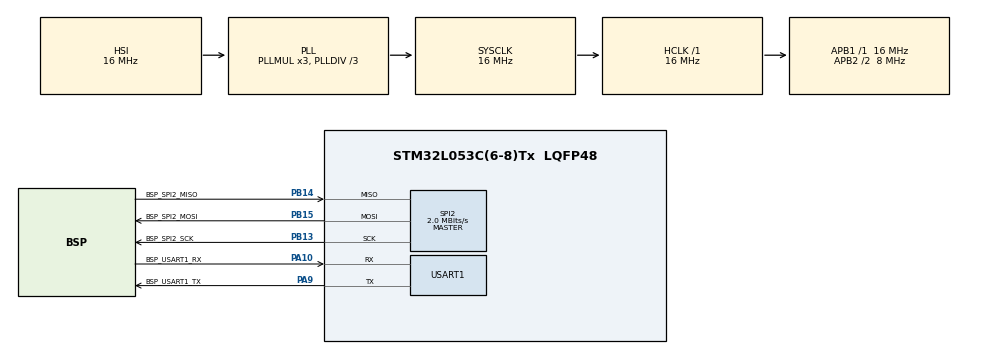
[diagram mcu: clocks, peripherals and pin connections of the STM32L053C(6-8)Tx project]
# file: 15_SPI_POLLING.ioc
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Mcu.Family=STM32L0
Mcu.Name=STM32L053C(6-8)Tx
Mcu.Package=LQFP48
PA10.GPIO_Label=BSP_USART1_RX
PA10.Mode=Asynchronous
PA10.Signal=USART1_RX
PA9.GPIO_Label=BSP_USART1_TX
PA9.Mode=Asynchronous
PA9.Signal=USART1_TX
PB13.GPIO_Label=BSP_SPI2_SCK
PB13.Mode=Full_Duplex_Master
PB13.Signal=SPI2_SCK
PB14.GPIO_Label=BSP_SPI2_MISO
PB14.Mode=Full_Duplex_Master
PB14.Signal=SPI2_MISO
PB15.GPIO_Label=BSP_SPI2_MOSI
PB15.Mode=Full_Duplex_Master
PB15.Signal=SPI2_MOSI
ProjectManager.HeapSize=0x200
ProjectManager.StackSize=0x400
ProjectManager.TargetToolchain=STM32CubeIDE
RCC.AHBFreq_Value=16000000
RCC.APB1Freq_Value=16000000
RCC.APB1TimFreq_Value=16000000
RCC.APB2CLKDivider=RCC_HCLK_DIV2
RCC.APB2Freq_Value=8000000
RCC.APB2TimFreq_Value=16000000
RCC.HCLKFreq_Value=16000000
RCC.HSE_VALUE=8000000
RCC.HSI16_VALUE=16000000
RCC.HSI48MClockSelection=RCC_USBCLKSOURCE_HSI48
RCC.HSI48_VALUE=48000000
RCC.HSI_VALUE=16000000
RCC.LSE_VALUE=32768
RCC.MSI_VALUE=2097000
RCC.PLLDIV=RCC_PLLDIV_3
RCC.RTCClockSelectionVirtual=RCC_RTCCLKSOURCE_LSE
RCC.SYSCLKFreq_VALUE=16000000
RCC.SYSCLKSource=RCC_SYSCLKSOURCE_PLLCLK
RCC.VCOOutputFreq_Value=48000000
SPI2.BaudRatePrescaler=SPI_BAUDRATEPRESCALER_8
SPI2.CalculateBaudRate=2.0 MBits/s
SPI2.Direction=SPI_DIRECTION_2LINES
SPI2.Mode=SPI_MODE_MASTER
SPI2.VirtualType=VM_MASTER
USART1.VirtualMode-Asynchronous=VM_ASYNC
board=STM32L0538-DISCO

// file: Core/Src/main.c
/* USER CODE BEGIN Header */
/**
  ******************************************************************************
  * @file           : main.c
  * @brief          : Main program body
  ******************************************************************************
  * @attention
  *
  * Copyright (c) 2024 STMicroelectronics.
  * All rights reserved.
  *
  * This software is licensed under terms that can be found in the LICENSE file
  * in the root directory of this software component.
  * If no LICENSE file comes with this software, it is provided AS-IS.
  *
  ******************************************************************************
  */
/* USER CODE END Header */
#include "main.h"

SPI_HandleTypeDef hspi2;

UART_HandleTypeDef huart1;

/* USER CODE BEGIN PV */
uint8_t tx_data[5] = "hello";
uint8_t rx_data[5];

/* USER CODE END PV */

void SystemClock_Config(void);
static void MX_GPIO_Init(void);
static void MX_USART1_UART_Init(void);
static void MX_SPI2_Init(void);

int main(void)
{

  /* MCU Configuration--------------------------------------------------------*/

  /* Reset of all peripherals, Initializes the Flash interface and the Systick. */
  HAL_Init();

  /* Configure the system clock */
  SystemClock_Config();

  /* Initialize all configured peripherals */
  MX_GPIO_Init();
  MX_USART1_UART_Init();
  MX_SPI2_Init();
  /* USER CODE BEGIN 2 */

//  HAL_SPI_TransmitReceive(&hspi1, tx_data, rx_data, sizeof(tx_data), 100);
//  HAL_SPI_Transmit(&hspi2, tx_data, sizeof(tx_data), 1000);
//  HAL_Delay(1000);
//  HAL_SPI_Receive(&hspi2, rx_data, sizeof(rx_data), 1000);
//  HAL_Delay(1000);
HAL_SPI_TransmitReceive(&hspi2, (uint8_t *)tx_data, (uint8_t *)rx_data, 5 , 1000);
HAL_Delay(500);
  /* USER CODE END 2 */

  /* Infinite loop */
  while (1)
  {

  }
}

void SystemClock_Config(void)
{
  RCC_OscInitTypeDef RCC_OscInitStruct = {0};
  RCC_ClkInitTypeDef RCC_ClkInitStruct = {0};
  RCC_PeriphCLKInitTypeDef PeriphClkInit = {0};

  /** Configure the main internal regulator output voltage
  */
  __HAL_PWR_VOLTAGESCALING_CONFIG(PWR_REGULATOR_VOLTAGE_SCALE1);

  /** Initializes the RCC Oscillators according to the specified parameters
  * in the RCC_OscInitTypeDef structure.
  */
  RCC_OscInitStruct.OscillatorType = RCC_OSCILLATORTYPE_HSI;
  RCC_OscInitStruct.HSIState = RCC_HSI_ON;
  RCC_OscInitStruct.HSICalibrationValue = RCC_HSICALIBRATION_DEFAULT;
  RCC_OscInitStruct.PLL.PLLState = RCC_PLL_ON;
  RCC_OscInitStruct.PLL.PLLSource = RCC_PLLSOURCE_HSI;
  RCC_OscInitStruct.PLL.PLLMUL = RCC_PLLMUL_3;
  RCC_OscInitStruct.PLL.PLLDIV = RCC_PLLDIV_3;
  if (HAL_RCC_OscConfig(&RCC_OscInitStruct) != HAL_OK)
  {
    Error_Handler();
  }

  /** Initializes the CPU, AHB and APB buses clocks
  */
  RCC_ClkInitStruct.ClockType = RCC_CLOCKTYPE_HCLK|RCC_CLOCKTYPE_SYSCLK
                              |RCC_CLOCKTYPE_PCLK1|RCC_CLOCKTYPE_PCLK2;
  RCC_ClkInitStruct.SYSCLKSource = RCC_SYSCLKSOURCE_PLLCLK;
  RCC_ClkInitStruct.AHBCLKDivider = RCC_SYSCLK_DIV1;
  RCC_ClkInitStruct.APB1CLKDivider = RCC_HCLK_DIV1;
  RCC_ClkInitStruct.APB2CLKDivider = RCC_HCLK_DIV2;

  if (HAL_RCC_ClockConfig(&RCC_ClkInitStruct, FLASH_LATENCY_0) != HAL_OK)
  {
    Error_Handler();
  }
  PeriphClkInit.PeriphClockSelection = RCC_PERIPHCLK_USART1;
  PeriphClkInit.Usart1ClockSelection = RCC_USART1CLKSOURCE_PCLK2;
  if (HAL_RCCEx_PeriphCLKConfig(&PeriphClkInit) != HAL_OK)
  {
    Error_Handler();
  }
}

static void MX_SPI2_Init(void)
{

  /* SPI2 parameter configuration*/
  hspi2.Instance = SPI2;
  hspi2.Init.Mode = SPI_MODE_MASTER;
  hspi2.Init.Direction = SPI_DIRECTION_2LINES;
  hspi2.Init.DataSize = SPI_DATASIZE_8BIT;
  hspi2.Init.CLKPolarity = SPI_POLARITY_LOW;
  hspi2.Init.CLKPhase = SPI_PHASE_1EDGE;
  hspi2.Init.NSS = SPI_NSS_SOFT;
  hspi2.Init.BaudRatePrescaler = SPI_BAUDRATEPRESCALER_8;
  hspi2.Init.FirstBit = SPI_FIRSTBIT_MSB;
  hspi2.Init.TIMode = SPI_TIMODE_DISABLE;
  hspi2.Init.CRCCalculation = SPI_CRCCALCULATION_DISABLE;
  hspi2.Init.CRCPolynomial = 7;
  if (HAL_SPI_Init(&hspi2) != HAL_OK)
  {
    Error_Handler();
  }

}

static void MX_USART1_UART_Init(void)
{

  huart1.Instance = USART1;
  huart1.Init.BaudRate = 115200;
  huart1.Init.WordLength = UART_WORDLENGTH_8B;
  huart1.Init.StopBits = UART_STOPBITS_1;
  huart1.Init.Parity = UART_PARITY_NONE;
  huart1.Init.Mode = UART_MODE_TX_RX;
  huart1.Init.HwFlowCtl = UART_HWCONTROL_NONE;
  huart1.Init.OverSampling = UART_OVERSAMPLING_16;
  huart1.Init.OneBitSampling = UART_ONE_BIT_SAMPLE_DISABLE;
  huart1.AdvancedInit.AdvFeatureInit = UART_ADVFEATURE_NO_INIT;
  if (HAL_UART_Init(&huart1) != HAL_OK)
  {
    Error_Handler();
  }

}

static void MX_GPIO_Init(void)
{

  /* GPIO Ports Clock Enable */
  __HAL_RCC_GPIOB_CLK_ENABLE();
  __HAL_RCC_GPIOA_CLK_ENABLE();

}

void Error_Handler(void)
{
  __disable_irq();
  while (1)
  {
  }
}
